# CH32V20x register map
Vendor: WCH Ltd.; File version: 1.0
Registers are 32-bit, read-write, reset 0x0 unless marked. A register's access mark holds for its fields unless they carry their own. Offsets are from the block's base; [hi:lo] are bit positions; {n}, {i} and the like mark numbered series; 'fields as' and 'values as' point back to an identical list.

## USB_OTG_FS — USB FS OTG register
Base 0x50000000
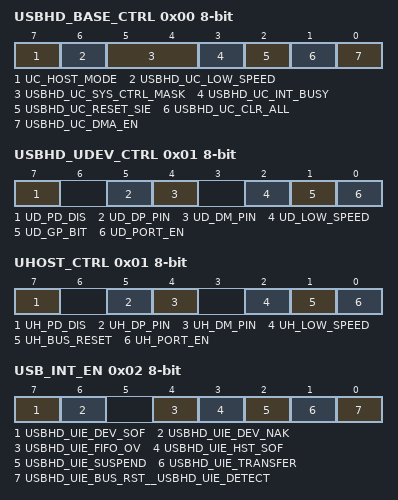
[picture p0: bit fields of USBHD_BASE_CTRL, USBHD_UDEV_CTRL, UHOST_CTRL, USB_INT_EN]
0x00 USBHD_BASE_CTRL 8-bit — USB base control
  [7] UC_HOST_MODE — enable USB host mode: 0=device mode, 1=host mode
  [6] USBHD_UC_LOW_SPEED — enable USB low speed: 0=12Mbps, 1=1.5Mbps
  [5:4] USBHD_UC_SYS_CTRL_MASK — USB device enable and internal pullup resistance enable
  [3] USBHD_UC_INT_BUSY — enable automatic responding busy for device mode or automatic pause for host mode during interrupt flag UIF_TRANSFER valid
  [2] USBHD_UC_RESET_SIE — force reset USB SIE, need software clear
  [1] USBHD_UC_CLR_ALL — force clear FIFO and count of USB
  [0] USBHD_UC_DMA_EN — DMA enable and DMA interrupt enable for USB
0x01 USBHD_UDEV_CTRL 8-bit access per field — USB device physical port control register
  [7] UD_PD_DIS rw — USB device port UD+/UD- pin internal pull-down resistor control
  [5] UD_DP_PIN ro — USB device port UD+ pin status
  [4] UD_DM_PIN ro — USB device port UD- pin status
  [2] UD_LOW_SPEED rw — USB device port low speed enable
  [1] UD_GP_BIT rw — USB device port general purpose bit
  [0] UD_PORT_EN rw — USB device port enable
0x01 UHOST_CTRL 8-bit — USB host physical port control register
  [7] UH_PD_DIS — Internal pull-down resistor control for USB host port UD+/UD- pins
  [5] UH_DP_PIN ro — Current UD+ pin status
  [4] UH_DM_PIN ro — Current UD- pin status
  [2] UH_LOW_SPEED — USB host port low speed enable
  [1] UH_BUS_RESET — USB host port bus reset
  [0] UH_PORT_EN — USB host port enable
0x02 USB_INT_EN 8-bit — USB interrupt enable
  [7] USBHD_UIE_DEV_SOF — enable interrupt for SOF received for USB device mode
  [6] USBHD_UIE_DEV_NAK — enable interrupt for NAK responded for USB device mode
  [4] USBHD_UIE_FIFO_OV — enable interrupt for FIFO overflow
  [3] USBHD_UIE_HST_SOF — enable interrupt for host SOF timer action for USB host mode
  [2] USBHD_UIE_SUSPEND — enable interrupt for USB suspend or resume event
  [1] USBHD_UIE_TRANSFER — enable interrupt for USB transfer completion
  [0] USBHD_UIE_BUS_RST__USBHD_UIE_DETECT — enable interrupt for USB bus reset event for USB device mode
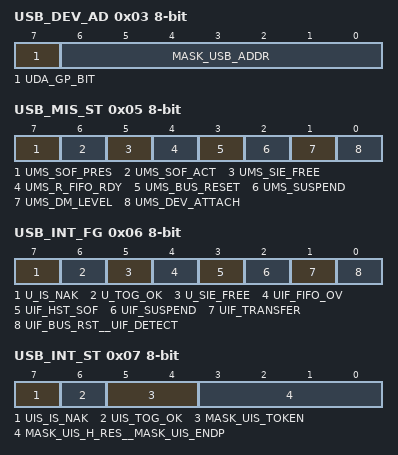
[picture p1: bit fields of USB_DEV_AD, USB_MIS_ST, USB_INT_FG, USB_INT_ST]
0x03 USB_DEV_AD 8-bit — USB device address
  [7] UDA_GP_BIT — general purpose bit
  [6:0] MASK_USB_ADDR — bit mask for USB device address
0x05 USB_MIS_ST 8-bit ro — USB miscellaneous status
  [7] UMS_SOF_PRES — RO, indicate host SOF timer presage status
  [6] UMS_SOF_ACT — RO, indicate host SOF timer action status for USB host
  [5] UMS_SIE_FREE — RO, indicate USB SIE free status
  [4] UMS_R_FIFO_RDY — RO, indicate USB receiving FIFO ready status (not empty)
  [3] UMS_BUS_RESET — RO, indicate USB bus reset status
  [2] UMS_SUSPEND — RO, indicate USB suspend status
  [1] UMS_DM_LEVEL — RO, indicate UDM level saved at device attached to USB host
  [0] UMS_DEV_ATTACH — RO, indicate device attached status on USB host
0x06 USB_INT_FG 8-bit — USB interrupt flag
  [7] U_IS_NAK ro — RO, indicate current USB transfer is NAK received
  [6] U_TOG_OK ro — RO, indicate current USB transfer toggle is OK
  [5] U_SIE_FREE ro — RO, indicate USB SIE free status
  [4] UIF_FIFO_OV — FIFO overflow interrupt flag for USB, direct bit address clear or write 1 to clear
  [3] UIF_HST_SOF — host SOF timer interrupt flag for USB host, direct bit address clear or write 1 to clear
  [2] UIF_SUSPEND — USB suspend or resume event interrupt flag, direct bit address clear or write 1 to clear
  [1] UIF_TRANSFER — USB transfer completion interrupt flag, direct bit address clear or write 1 to clear
  [0] UIF_BUS_RST__UIF_DETECT — bus reset event interrupt flag for USB device mode, direct bit address clear or write 1 to clear;device detected event interrupt flag for USB host mode, direct bit address clear or write 1 to clear
0x07 USB_INT_ST 8-bit ro — USB interrupt status
  [7] UIS_IS_NAK — RO, indicate current USB transfer is NAK received for USB device mode
  [6] UIS_TOG_OK — RO, indicate current USB transfer toggle is OK
  [5:4] MASK_UIS_TOKEN — RO, bit mask of current token PID code received for USB device mode
  [3:0] MASK_UIS_H_RES__MASK_UIS_ENDP — RO, bit mask of current transfer handshake response for USB host mode: 0000=no response, time out from device, others=handshake response PID received;RO, bit mask of current transfer endpoint number for USB device mode
0x08 USB_RX_LEN 16-bit ro — USB receiving length
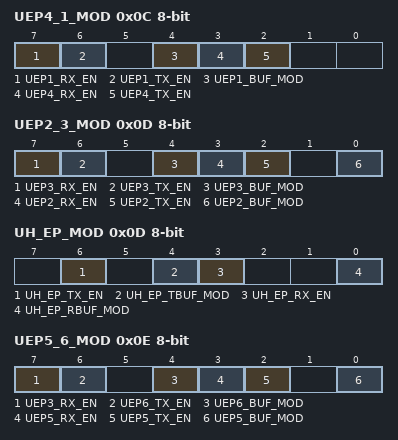
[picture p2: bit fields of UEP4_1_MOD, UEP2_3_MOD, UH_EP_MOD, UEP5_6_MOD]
0x0C UEP4_1_MOD 8-bit — endpoint 4/1 mode
  [7] UEP1_RX_EN — enable USB endpoint 1 receiving (OUT)
  [6] UEP1_TX_EN — enable USB endpoint 1 transmittal (IN)
  [4] UEP1_BUF_MOD — buffer mode of USB endpoint 1
  [3] UEP4_RX_EN — enable USB endpoint 4 receiving (OUT)
  [2] UEP4_TX_EN — enable USB endpoint 4 transmittal (IN)
0x0D UEP2_3_MOD 8-bit — Endpoint 2/3 mode control register
  [7] UEP3_RX_EN, [6] UEP3_TX_EN, [4] UEP3_BUF_MOD, [3] UEP2_RX_EN, [2] UEP2_TX_EN, [0] UEP2_BUF_MOD
0x0D UH_EP_MOD 8-bit — USB host endpoint mode control register
  [6] UH_EP_TX_EN, [4] UH_EP_TBUF_MOD, [3] UH_EP_RX_EN, [0] UH_EP_RBUF_MOD
0x0E UEP5_6_MOD 8-bit — endpoint 5/6 mode
  [7] UEP3_RX_EN — enable USB endpoint 6 receiving (OUT)
  [6] UEP6_TX_EN — enable USB endpoint 6 transmittal (IN)
  [4] UEP6_BUF_MOD — buffer mode of USB endpoint 6
  [3] UEP5_RX_EN — enable USB endpoint 5 receiving (OUT)
  [2] UEP5_TX_EN — enable USB endpoint 5 transmittal (IN)
  [0] UEP5_BUF_MOD — buffer mode of USB endpoint 5
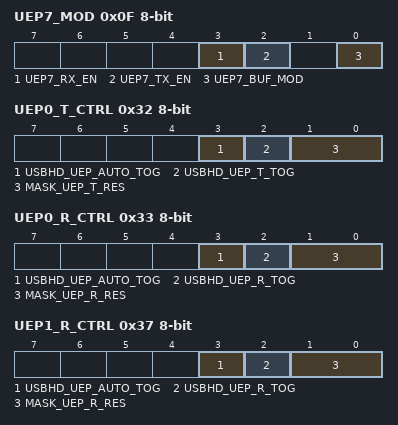
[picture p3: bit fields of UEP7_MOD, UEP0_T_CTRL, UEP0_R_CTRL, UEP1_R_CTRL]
0x0F UEP7_MOD 8-bit — endpoint 7 mode
  [3] UEP7_RX_EN — enable USB endpoint 7 receiving (OUT)
  [2] UEP7_TX_EN — enable USB endpoint 7 transmittal (IN)
  [0] UEP7_BUF_MOD — buffer mode of USB endpoint 7
0x10 UEP0_DMA — endpoint 0 DMA buffer address
0x14 UEP1_DMA — endpoint 1 DMA buffer address
0x18 UEP2_DMA 16-bit
0x18 UH_RX_DMA 16-bit
0x1C UEP3_DMA 16-bit
0x1C UH_TX_DMA 16-bit
{0x10+4i} UEP{i}_DMA (i=4..7) — endpoint {i} DMA buffer address
0x30 UEP0_T_LEN 8-bit — endpoint 0 transmittal length
0x32 UEP0_T_CTRL 8-bit — endpoint 0 control
  [3] USBHD_UEP_AUTO_TOG — enable automatic toggle after successful transfer completion on endpoint 1/2/3: 0=manual toggle, 1=automatic toggle
  [2] USBHD_UEP_T_TOG — prepared data toggle flag of USB endpoint X transmittal (IN): 0=DATA0, 1=DATA1
  [1:0] MASK_UEP_T_RES — bit mask of handshake response type for USB endpoint X transmittal (IN)
0x33 UEP0_R_CTRL 8-bit — endpoint 0 control
  [3] USBHD_UEP_AUTO_TOG — enable automatic toggle after successful transfer completion on endpoint 1/2/3: 0=manual toggle, 1=automatic toggle
  [2] USBHD_UEP_R_TOG — expected data toggle flag of USB endpoint X receiving (OUT): 0=DATA0, 1=DATA1
  [1:0] MASK_UEP_R_RES — bit mask of handshake response type for USB endpoint X receiving (OUT)
0x34 UEP1_T_LEN 8-bit — endpoint 1 transmittal length
0x36 UEP1_TX_CTRL 8-bit
0x36 UH_SETUP 8-bit
0x37 UEP1_R_CTRL 8-bit — endpoint 1 control
  fields as UEP0_R_CTRL
0x38 UEP2_T_LEN 8-bit
0x38 UH_EP_PID 8-bit
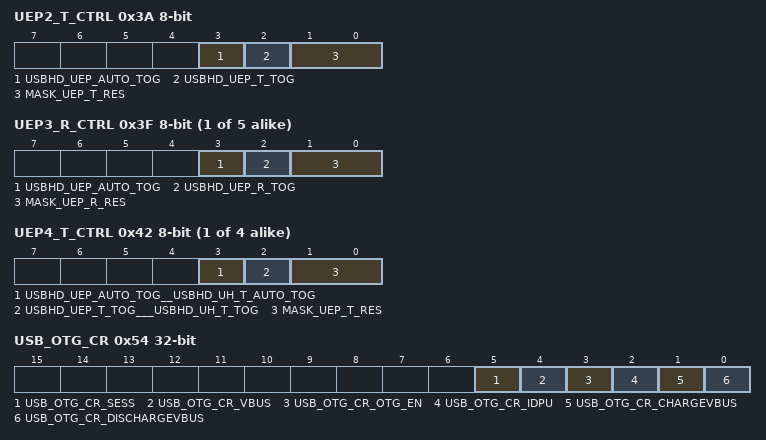
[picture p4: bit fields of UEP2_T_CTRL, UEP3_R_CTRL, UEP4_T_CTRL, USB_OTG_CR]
0x3A UEP2_T_CTRL 8-bit — endpoint 2 control
  fields as UEP0_T_CTRL
0x3A UH_RX_CTRL 8-bit
0x3B UEP2_RX_CTRL 8-bit
0x3C UEP3_T_LEN 8-bit
0x3C UH_TX_LEN 8-bit
0x3E UEP3_TX_CTRL 8-bit
0x3E UH_TX_CTRL 8-bit
{0x33+4i} UEP{i}_R_CTRL 8-bit (i=3..7) — endpoint {i} control
  fields as UEP0_R_CTRL
{0x30+4i} UEP{i}_T_LEN 8-bit (i=4..7) — endpoint {i} transmittal length
{0x32+4i} UEP{i}_T_CTRL 8-bit (i=4..7) — endpoint {i} control
  [3] USBHD_UEP_AUTO_TOG__USBHD_UH_T_AUTO_TOG — enable automatic toggle after successful transfer completion on endpoint 1/2/3: 0=manual toggle, 1=automatic toggle
  [2] USBHD_UEP_T_TOG___USBHD_UH_T_TOG — prepared data toggle flag of USB endpoint X transmittal (IN): 0=DATA0, 1=DATA1
  [1:0] MASK_UEP_T_RES — bit mask of handshake response type for USB endpoint X transmittal (IN)
0x54 USB_OTG_CR — usb otg control
  [5] USB_OTG_CR_SESS — usb otg control
  [4] USB_OTG_CR_VBUS — usb otg control
  [3] USB_OTG_CR_OTG_EN — usb otg control
  [2] USB_OTG_CR_IDPU — usb otg control
  [1] USB_OTG_CR_CHARGEVBUS — usb otg control
  [0] USB_OTG_CR_DISCHARGEVBUS — usb otg control
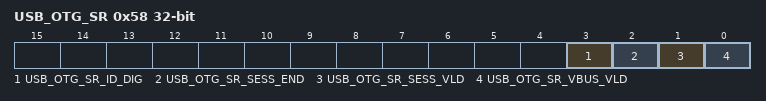
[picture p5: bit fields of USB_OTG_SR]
0x58 USB_OTG_SR — usb otg status
  [3] USB_OTG_SR_ID_DIG — usb otg status
  [2] USB_OTG_SR_SESS_END — usb otg status
  [1] USB_OTG_SR_SESS_VLD — usb otg status
  [0] USB_OTG_SR_VBUS_VLD — usb otg status
